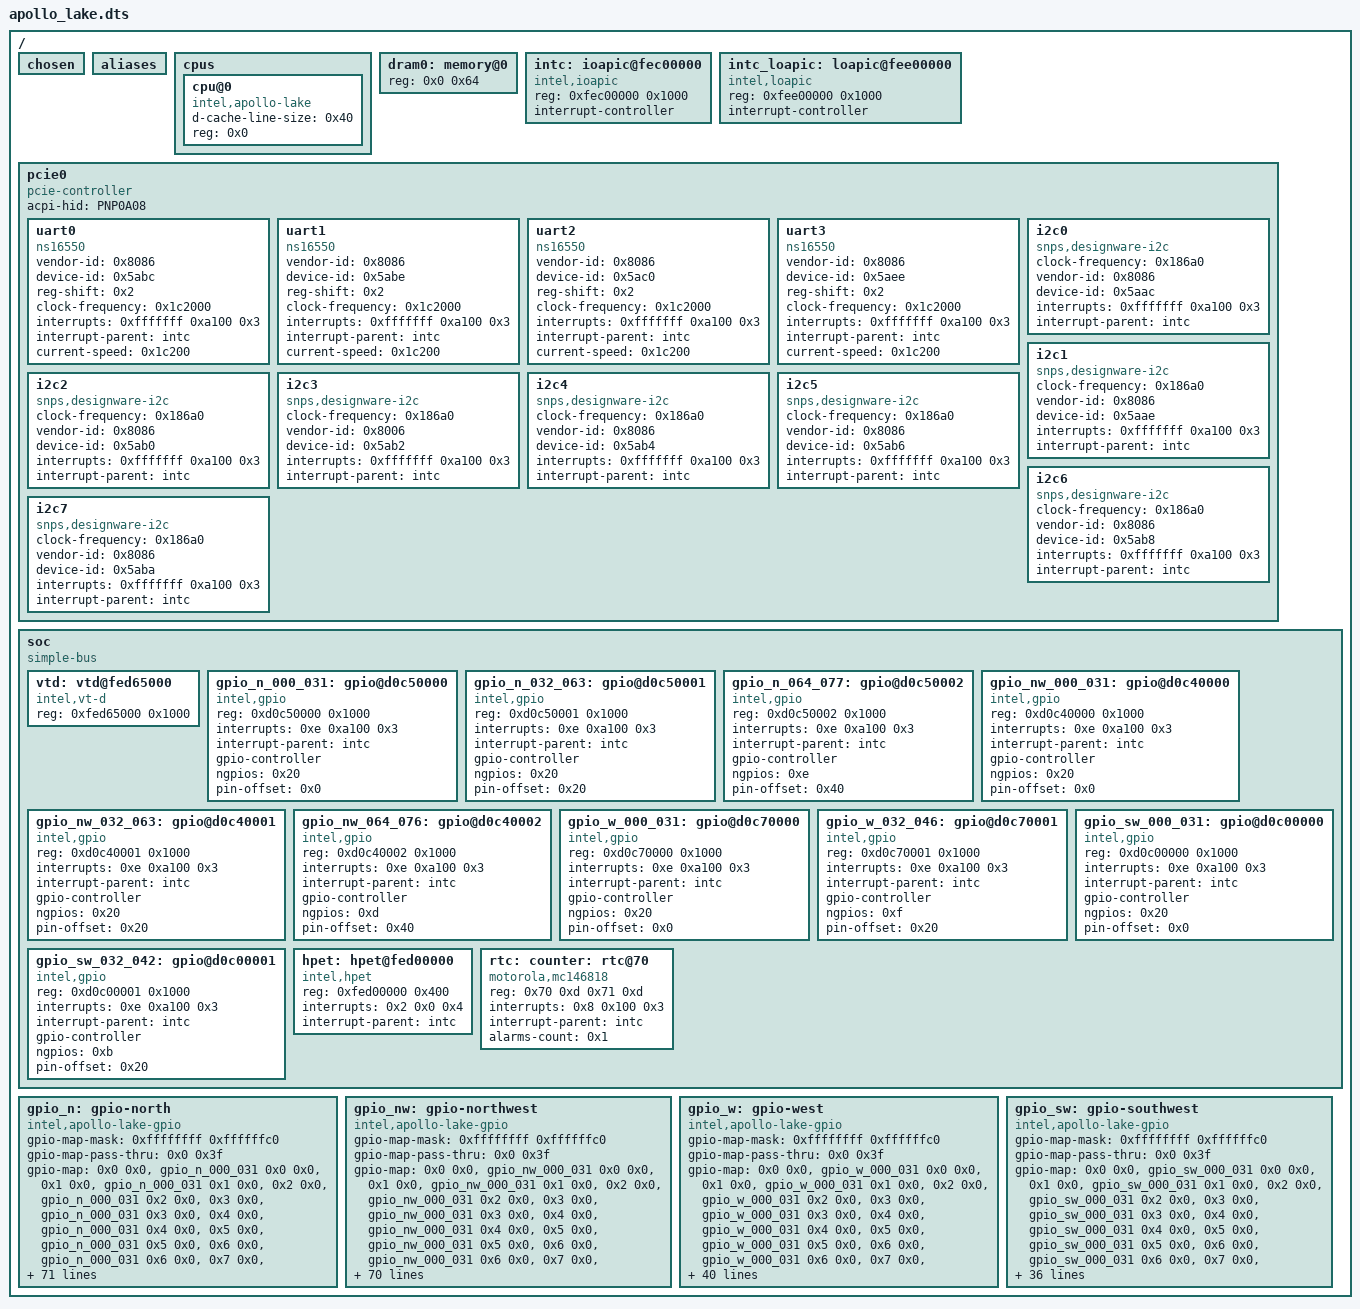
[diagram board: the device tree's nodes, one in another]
/dts-v1/;

/ {
	#address-cells = < 0x1 >;
	#size-cells = < 0x1 >;
	chosen {
	};
	aliases {
	};
	cpus {
		#address-cells = < 0x1 >;
		#size-cells = < 0x0 >;
		cpu@0 {
			device_type = "cpu";
			compatible = "intel,apollo-lake";
			d-cache-line-size = < 0x40 >;
			reg = < 0x0 >;
		};
	};
	dram0: memory@0 {
		device_type = "memory";
		reg = < 0x0 0x64 >;
	};
	intc: ioapic@fec00000 {
		compatible = "intel,ioapic";
		#address-cells = < 0x1 >;
		#interrupt-cells = < 0x3 >;
		reg = < 0xfec00000 0x1000 >;
		interrupt-controller;
		phandle = < 0x1 >;
	};
	intc_loapic: loapic@fee00000 {
		compatible = "intel,loapic";
		reg = < 0xfee00000 0x1000 >;
		interrupt-controller;
		#interrupt-cells = < 0x3 >;
		#address-cells = < 0x1 >;
	};
	pcie0: pcie0 {
		#address-cells = < 0x1 >;
		#size-cells = < 0x1 >;
		compatible = "pcie-controller";
		acpi-hid = "PNP0A08";
		ranges;
		uart0: uart0 {
			compatible = "ns16550";
			vendor-id = < 0x8086 >;
			device-id = < 0x5abc >;
			reg-shift = < 0x2 >;
			clock-frequency = < 0x1c2000 >;
			interrupts = < 0xfffffff 0xa100 0x3 >;
			interrupt-parent = < &intc >;
			status = "okay";
			current-speed = < 0x1c200 >;
		};
		uart1: uart1 {
			compatible = "ns16550";
			vendor-id = < 0x8086 >;
			device-id = < 0x5abe >;
			reg-shift = < 0x2 >;
			clock-frequency = < 0x1c2000 >;
			interrupts = < 0xfffffff 0xa100 0x3 >;
			interrupt-parent = < &intc >;
			status = "okay";
			current-speed = < 0x1c200 >;
		};
		uart2: uart2 {
			compatible = "ns16550";
			vendor-id = < 0x8086 >;
			device-id = < 0x5ac0 >;
			reg-shift = < 0x2 >;
			clock-frequency = < 0x1c2000 >;
			interrupts = < 0xfffffff 0xa100 0x3 >;
			interrupt-parent = < &intc >;
			status = "okay";
			current-speed = < 0x1c200 >;
		};
		uart3: uart3 {
			compatible = "ns16550";
			vendor-id = < 0x8086 >;
			device-id = < 0x5aee >;
			reg-shift = < 0x2 >;
			clock-frequency = < 0x1c2000 >;
			interrupts = < 0xfffffff 0xa100 0x3 >;
			interrupt-parent = < &intc >;
			status = "okay";
			current-speed = < 0x1c200 >;
		};
		i2c0: i2c0 {
			compatible = "snps,designware-i2c";
			clock-frequency = < 0x186a0 >;
			#address-cells = < 0x1 >;
			#size-cells = < 0x0 >;
			vendor-id = < 0x8086 >;
			device-id = < 0x5aac >;
			interrupts = < 0xfffffff 0xa100 0x3 >;
			interrupt-parent = < &intc >;
			status = "okay";
		};
		i2c1: i2c1 {
			compatible = "snps,designware-i2c";
			clock-frequency = < 0x186a0 >;
			#address-cells = < 0x1 >;
			#size-cells = < 0x0 >;
			vendor-id = < 0x8086 >;
			device-id = < 0x5aae >;
			interrupts = < 0xfffffff 0xa100 0x3 >;
			interrupt-parent = < &intc >;
			status = "okay";
		};
		i2c2: i2c2 {
			compatible = "snps,designware-i2c";
			clock-frequency = < 0x186a0 >;
			#address-cells = < 0x1 >;
			#size-cells = < 0x0 >;
			vendor-id = < 0x8086 >;
			device-id = < 0x5ab0 >;
			interrupts = < 0xfffffff 0xa100 0x3 >;
			interrupt-parent = < &intc >;
			status = "okay";
		};
		i2c3: i2c3 {
			compatible = "snps,designware-i2c";
			clock-frequency = < 0x186a0 >;
			#address-cells = < 0x1 >;
			#size-cells = < 0x0 >;
			vendor-id = < 0x8006 >;
			device-id = < 0x5ab2 >;
			interrupts = < 0xfffffff 0xa100 0x3 >;
			interrupt-parent = < &intc >;
			status = "okay";
		};
		i2c4: i2c4 {
			compatible = "snps,designware-i2c";
			clock-frequency = < 0x186a0 >;
			#address-cells = < 0x1 >;
			#size-cells = < 0x0 >;
			vendor-id = < 0x8086 >;
			device-id = < 0x5ab4 >;
			interrupts = < 0xfffffff 0xa100 0x3 >;
			interrupt-parent = < &intc >;
			status = "okay";
		};
		i2c5: i2c5 {
			compatible = "snps,designware-i2c";
			clock-frequency = < 0x186a0 >;
			#address-cells = < 0x1 >;
			#size-cells = < 0x0 >;
			vendor-id = < 0x8086 >;
			device-id = < 0x5ab6 >;
			interrupts = < 0xfffffff 0xa100 0x3 >;
			interrupt-parent = < &intc >;
			status = "okay";
		};
		i2c6: i2c6 {
			compatible = "snps,designware-i2c";
			clock-frequency = < 0x186a0 >;
			#address-cells = < 0x1 >;
			#size-cells = < 0x0 >;
			vendor-id = < 0x8086 >;
			device-id = < 0x5ab8 >;
			interrupts = < 0xfffffff 0xa100 0x3 >;
			interrupt-parent = < &intc >;
			status = "okay";
		};
		i2c7: i2c7 {
			compatible = "snps,designware-i2c";
			clock-frequency = < 0x186a0 >;
			#address-cells = < 0x1 >;
			#size-cells = < 0x0 >;
			vendor-id = < 0x8086 >;
			device-id = < 0x5aba >;
			interrupts = < 0xfffffff 0xa100 0x3 >;
			interrupt-parent = < &intc >;
			status = "okay";
		};
	};
	soc {
		#address-cells = < 0x1 >;
		#size-cells = < 0x1 >;
		compatible = "simple-bus";
		ranges;
		vtd: vtd@fed65000 {
			compatible = "intel,vt-d";
			reg = < 0xfed65000 0x1000 >;
			status = "okay";
		};
		gpio_n_000_031: gpio@d0c50000 {
			compatible = "intel,gpio";
			reg = < 0xd0c50000 0x1000 >;
			interrupts = < 0xe 0xa100 0x3 >;
			interrupt-parent = < &intc >;
			gpio-controller;
			#gpio-cells = < 0x2 >;
			ngpios = < 0x20 >;
			pin-offset = < 0x0 >;
			status = "okay";
			phandle = < 0x2 >;
		};
		gpio_n_032_063: gpio@d0c50001 {
			compatible = "intel,gpio";
			reg = < 0xd0c50001 0x1000 >;
			interrupts = < 0xe 0xa100 0x3 >;
			interrupt-parent = < &intc >;
			gpio-controller;
			#gpio-cells = < 0x2 >;
			ngpios = < 0x20 >;
			pin-offset = < 0x20 >;
			status = "okay";
			phandle = < 0x3 >;
		};
		gpio_n_064_077: gpio@d0c50002 {
			compatible = "intel,gpio";
			reg = < 0xd0c50002 0x1000 >;
			interrupts = < 0xe 0xa100 0x3 >;
			interrupt-parent = < &intc >;
			gpio-controller;
			#gpio-cells = < 0x2 >;
			ngpios = < 0xe >;
			pin-offset = < 0x40 >;
			status = "okay";
			phandle = < 0x4 >;
		};
		gpio_nw_000_031: gpio@d0c40000 {
			compatible = "intel,gpio";
			reg = < 0xd0c40000 0x1000 >;
			interrupts = < 0xe 0xa100 0x3 >;
			interrupt-parent = < &intc >;
			gpio-controller;
			#gpio-cells = < 0x2 >;
			ngpios = < 0x20 >;
			pin-offset = < 0x0 >;
			status = "okay";
			phandle = < 0x5 >;
		};
		gpio_nw_032_063: gpio@d0c40001 {
			compatible = "intel,gpio";
			reg = < 0xd0c40001 0x1000 >;
			interrupts = < 0xe 0xa100 0x3 >;
			interrupt-parent = < &intc >;
			gpio-controller;
			#gpio-cells = < 0x2 >;
			ngpios = < 0x20 >;
			pin-offset = < 0x20 >;
			status = "okay";
			phandle = < 0x6 >;
		};
		gpio_nw_064_076: gpio@d0c40002 {
			compatible = "intel,gpio";
			reg = < 0xd0c40002 0x1000 >;
			interrupts = < 0xe 0xa100 0x3 >;
			interrupt-parent = < &intc >;
			gpio-controller;
			#gpio-cells = < 0x2 >;
			ngpios = < 0xd >;
			pin-offset = < 0x40 >;
			status = "okay";
			phandle = < 0x7 >;
		};
		gpio_w_000_031: gpio@d0c70000 {
			compatible = "intel,gpio";
			reg = < 0xd0c70000 0x1000 >;
			interrupts = < 0xe 0xa100 0x3 >;
			interrupt-parent = < &intc >;
			gpio-controller;
			#gpio-cells = < 0x2 >;
			ngpios = < 0x20 >;
			pin-offset = < 0x0 >;
			status = "okay";
			phandle = < 0x8 >;
		};
		gpio_w_032_046: gpio@d0c70001 {
			compatible = "intel,gpio";
			reg = < 0xd0c70001 0x1000 >;
			interrupts = < 0xe 0xa100 0x3 >;
			interrupt-parent = < &intc >;
			gpio-controller;
			#gpio-cells = < 0x2 >;
			ngpios = < 0xf >;
			pin-offset = < 0x20 >;
			status = "okay";
			phandle = < 0x9 >;
		};
		gpio_sw_000_031: gpio@d0c00000 {
			compatible = "intel,gpio";
			reg = < 0xd0c00000 0x1000 >;
			interrupts = < 0xe 0xa100 0x3 >;
			interrupt-parent = < &intc >;
			gpio-controller;
			#gpio-cells = < 0x2 >;
			ngpios = < 0x20 >;
			pin-offset = < 0x0 >;
			status = "okay";
			phandle = < 0xa >;
		};
		gpio_sw_032_042: gpio@d0c00001 {
			compatible = "intel,gpio";
			reg = < 0xd0c00001 0x1000 >;
			interrupts = < 0xe 0xa100 0x3 >;
			interrupt-parent = < &intc >;
			gpio-controller;
			#gpio-cells = < 0x2 >;
			ngpios = < 0xb >;
			pin-offset = < 0x20 >;
			status = "okay";
			phandle = < 0xb >;
		};
		hpet: hpet@fed00000 {
			compatible = "intel,hpet";
			reg = < 0xfed00000 0x400 >;
			interrupts = < 0x2 0x0 0x4 >;
			interrupt-parent = < &intc >;
			status = "okay";
		};
		rtc: counter: rtc@70 {
			compatible = "motorola,mc146818";
			reg = < 0x70 0xd 0x71 0xd >;
			interrupts = < 0x8 0x100 0x3 >;
			interrupt-parent = < &intc >;
			alarms-count = < 0x1 >;
			status = "okay";
		};
	};
	gpio_n: gpio-north {
		compatible = "intel,apollo-lake-gpio";
		#gpio-cells = < 0x2 >;
		gpio-map-mask = < 0xffffffff 0xffffffc0 >;
		gpio-map-pass-thru = < 0x0 0x3f >;
		gpio-map = < 0x0 0x0 &gpio_n_000_031 0x0 0x0 >, < 0x1 0x0 &gpio_n_000_031 0x1 0x0 >, < 0x2 0x0 &gpio_n_000_031 0x2 0x0 >, < 0x3 0x0 &gpio_n_000_031 0x3 0x0 >, < 0x4 0x0 &gpio_n_000_031 0x4 0x0 >, < 0x5 0x0 &gpio_n_000_031 0x5 0x0 >, < 0x6 0x0 &gpio_n_000_031 0x6 0x0 >, < 0x7 0x0 &gpio_n_000_031 0x7 0x0 >, < 0x8 0x0 &gpio_n_000_031 0x8 0x0 >, < 0x9 0x0 &gpio_n_000_031 0x9 0x0 >, < 0xa 0x0 &gpio_n_000_031 0xa 0x0 >, < 0xb 0x0 &gpio_n_000_031 0xb 0x0 >, < 0xc 0x0 &gpio_n_000_031 0xc 0x0 >, < 0xd 0x0 &gpio_n_000_031 0xd 0x0 >, < 0xe 0x0 &gpio_n_000_031 0xe 0x0 >, < 0xf 0x0 &gpio_n_000_031 0xf 0x0 >, < 0x10 0x0 &gpio_n_000_031 0x10 0x0 >, < 0x11 0x0 &gpio_n_000_031 0x11 0x0 >, < 0x12 0x0 &gpio_n_000_031 0x12 0x0 >, < 0x13 0x0 &gpio_n_000_031 0x13 0x0 >, < 0x14 0x0 &gpio_n_000_031 0x14 0x0 >, < 0x15 0x0 &gpio_n_000_031 0x15 0x0 >, < 0x16 0x0 &gpio_n_000_031 0x16 0x0 >, < 0x17 0x0 &gpio_n_000_031 0x17 0x0 >, < 0x18 0x0 &gpio_n_000_031 0x18 0x0 >, < 0x19 0x0 &gpio_n_000_031 0x19 0x0 >, < 0x1a 0x0 &gpio_n_000_031 0x1a 0x0 >, < 0x1b 0x0 &gpio_n_000_031 0x1b 0x0 >, < 0x1c 0x0 &gpio_n_000_031 0x1c 0x0 >, < 0x1d 0x0 &gpio_n_000_031 0x1d 0x0 >, < 0x1e 0x0 &gpio_n_000_031 0x1e 0x0 >, < 0x1f 0x0 &gpio_n_000_031 0x1f 0x0 >, < 0x20 0x0 &gpio_n_032_063 0x0 0x0 >, < 0x21 0x0 &gpio_n_032_063 0x1 0x0 >, < 0x22 0x0 &gpio_n_032_063 0x2 0x0 >, < 0x23 0x0 &gpio_n_032_063 0x3 0x0 >, < 0x24 0x0 &gpio_n_032_063 0x4 0x0 >, < 0x25 0x0 &gpio_n_032_063 0x5 0x0 >, < 0x26 0x0 &gpio_n_032_063 0x6 0x0 >, < 0x27 0x0 &gpio_n_032_063 0x7 0x0 >, < 0x28 0x0 &gpio_n_032_063 0x8 0x0 >, < 0x29 0x0 &gpio_n_032_063 0x9 0x0 >, < 0x2a 0x0 &gpio_n_032_063 0xa 0x0 >, < 0x2b 0x0 &gpio_n_032_063 0xb 0x0 >, < 0x2c 0x0 &gpio_n_032_063 0xc 0x0 >, < 0x2d 0x0 &gpio_n_032_063 0xd 0x0 >, < 0x2e 0x0 &gpio_n_032_063 0xe 0x0 >, < 0x2f 0x0 &gpio_n_032_063 0xf 0x0 >, < 0x30 0x0 &gpio_n_032_063 0x10 0x0 >, < 0x31 0x0 &gpio_n_032_063 0x11 0x0 >, < 0x32 0x0 &gpio_n_032_063 0x12 0x0 >, < 0x33 0x0 &gpio_n_032_063 0x13 0x0 >, < 0x34 0x0 &gpio_n_032_063 0x14 0x0 >, < 0x35 0x0 &gpio_n_032_063 0x15 0x0 >, < 0x36 0x0 &gpio_n_032_063 0x16 0x0 >, < 0x37 0x0 &gpio_n_032_063 0x17 0x0 >, < 0x38 0x0 &gpio_n_032_063 0x18 0x0 >, < 0x39 0x0 &gpio_n_032_063 0x19 0x0 >, < 0x3a 0x0 &gpio_n_032_063 0x1a 0x0 >, < 0x3b 0x0 &gpio_n_032_063 0x1b 0x0 >, < 0x3c 0x0 &gpio_n_032_063 0x1c 0x0 >, < 0x3d 0x0 &gpio_n_032_063 0x1d 0x0 >, < 0x3e 0x0 &gpio_n_032_063 0x1e 0x0 >, < 0x3f 0x0 &gpio_n_032_063 0x1f 0x0 >, < 0x40 0x0 &gpio_n_064_077 0x0 0x0 >, < 0x41 0x0 &gpio_n_064_077 0x1 0x0 >, < 0x42 0x0 &gpio_n_064_077 0x2 0x0 >, < 0x43 0x0 &gpio_n_064_077 0x3 0x0 >, < 0x44 0x0 &gpio_n_064_077 0x4 0x0 >, < 0x45 0x0 &gpio_n_064_077 0x5 0x0 >, < 0x46 0x0 &gpio_n_064_077 0x6 0x0 >, < 0x47 0x0 &gpio_n_064_077 0x7 0x0 >, < 0x48 0x0 &gpio_n_064_077 0x8 0x0 >, < 0x49 0x0 &gpio_n_064_077 0x9 0x0 >, < 0x4a 0x0 &gpio_n_064_077 0xa 0x0 >, < 0x4b 0x0 &gpio_n_064_077 0xb 0x0 >, < 0x4c 0x0 &gpio_n_064_077 0xc 0x0 >, < 0x4d 0x0 &gpio_n_064_077 0xd 0x0 >;
	};
	gpio_nw: gpio-northwest {
		compatible = "intel,apollo-lake-gpio";
		#gpio-cells = < 0x2 >;
		gpio-map-mask = < 0xffffffff 0xffffffc0 >;
		gpio-map-pass-thru = < 0x0 0x3f >;
		gpio-map = < 0x0 0x0 &gpio_nw_000_031 0x0 0x0 >, < 0x1 0x0 &gpio_nw_000_031 0x1 0x0 >, < 0x2 0x0 &gpio_nw_000_031 0x2 0x0 >, < 0x3 0x0 &gpio_nw_000_031 0x3 0x0 >, < 0x4 0x0 &gpio_nw_000_031 0x4 0x0 >, < 0x5 0x0 &gpio_nw_000_031 0x5 0x0 >, < 0x6 0x0 &gpio_nw_000_031 0x6 0x0 >, < 0x7 0x0 &gpio_nw_000_031 0x7 0x0 >, < 0x8 0x0 &gpio_nw_000_031 0x8 0x0 >, < 0x9 0x0 &gpio_nw_000_031 0x9 0x0 >, < 0xa 0x0 &gpio_nw_000_031 0xa 0x0 >, < 0xb 0x0 &gpio_nw_000_031 0xb 0x0 >, < 0xc 0x0 &gpio_nw_000_031 0xc 0x0 >, < 0xd 0x0 &gpio_nw_000_031 0xd 0x0 >, < 0xe 0x0 &gpio_nw_000_031 0xe 0x0 >, < 0xf 0x0 &gpio_nw_000_031 0xf 0x0 >, < 0x10 0x0 &gpio_nw_000_031 0x10 0x0 >, < 0x11 0x0 &gpio_nw_000_031 0x11 0x0 >, < 0x12 0x0 &gpio_nw_000_031 0x12 0x0 >, < 0x13 0x0 &gpio_nw_000_031 0x13 0x0 >, < 0x14 0x0 &gpio_nw_000_031 0x14 0x0 >, < 0x15 0x0 &gpio_nw_000_031 0x15 0x0 >, < 0x16 0x0 &gpio_nw_000_031 0x16 0x0 >, < 0x17 0x0 &gpio_nw_000_031 0x17 0x0 >, < 0x18 0x0 &gpio_nw_000_031 0x18 0x0 >, < 0x19 0x0 &gpio_nw_000_031 0x19 0x0 >, < 0x1a 0x0 &gpio_nw_000_031 0x1a 0x0 >, < 0x1b 0x0 &gpio_nw_000_031 0x1b 0x0 >, < 0x1c 0x0 &gpio_nw_000_031 0x1c 0x0 >, < 0x1d 0x0 &gpio_nw_000_031 0x1d 0x0 >, < 0x1e 0x0 &gpio_nw_000_031 0x1e 0x0 >, < 0x1f 0x0 &gpio_nw_000_031 0x1f 0x0 >, < 0x20 0x0 &gpio_nw_032_063 0x0 0x0 >, < 0x21 0x0 &gpio_nw_032_063 0x1 0x0 >, < 0x22 0x0 &gpio_nw_032_063 0x2 0x0 >, < 0x23 0x0 &gpio_nw_032_063 0x3 0x0 >, < 0x24 0x0 &gpio_nw_032_063 0x4 0x0 >, < 0x25 0x0 &gpio_nw_032_063 0x5 0x0 >, < 0x26 0x0 &gpio_nw_032_063 0x6 0x0 >, < 0x27 0x0 &gpio_nw_032_063 0x7 0x0 >, < 0x28 0x0 &gpio_nw_032_063 0x8 0x0 >, < 0x29 0x0 &gpio_nw_032_063 0x9 0x0 >, < 0x2a 0x0 &gpio_nw_032_063 0xa 0x0 >, < 0x2b 0x0 &gpio_nw_032_063 0xb 0x0 >, < 0x2c 0x0 &gpio_nw_032_063 0xc 0x0 >, < 0x2d 0x0 &gpio_nw_032_063 0xd 0x0 >, < 0x2e 0x0 &gpio_nw_032_063 0xe 0x0 >, < 0x2f 0x0 &gpio_nw_032_063 0xf 0x0 >, < 0x30 0x0 &gpio_nw_032_063 0x10 0x0 >, < 0x31 0x0 &gpio_nw_032_063 0x11 0x0 >, < 0x32 0x0 &gpio_nw_032_063 0x12 0x0 >, < 0x33 0x0 &gpio_nw_032_063 0x13 0x0 >, < 0x34 0x0 &gpio_nw_032_063 0x14 0x0 >, < 0x35 0x0 &gpio_nw_032_063 0x15 0x0 >, < 0x36 0x0 &gpio_nw_032_063 0x16 0x0 >, < 0x37 0x0 &gpio_nw_032_063 0x17 0x0 >, < 0x38 0x0 &gpio_nw_032_063 0x18 0x0 >, < 0x39 0x0 &gpio_nw_032_063 0x19 0x0 >, < 0x3a 0x0 &gpio_nw_032_063 0x1a 0x0 >, < 0x3b 0x0 &gpio_nw_032_063 0x1b 0x0 >, < 0x3c 0x0 &gpio_nw_032_063 0x1c 0x0 >, < 0x3d 0x0 &gpio_nw_032_063 0x1d 0x0 >, < 0x3e 0x0 &gpio_nw_032_063 0x1e 0x0 >, < 0x3f 0x0 &gpio_nw_032_063 0x1f 0x0 >, < 0x40 0x0 &gpio_nw_064_076 0x0 0x0 >, < 0x41 0x0 &gpio_nw_064_076 0x1 0x0 >, < 0x42 0x0 &gpio_nw_064_076 0x2 0x0 >, < 0x43 0x0 &gpio_nw_064_076 0x3 0x0 >, < 0x44 0x0 &gpio_nw_064_076 0x4 0x0 >, < 0x45 0x0 &gpio_nw_064_076 0x5 0x0 >, < 0x46 0x0 &gpio_nw_064_076 0x6 0x0 >, < 0x47 0x0 &gpio_nw_064_076 0x7 0x0 >, < 0x48 0x0 &gpio_nw_064_076 0x8 0x0 >, < 0x49 0x0 &gpio_nw_064_076 0x9 0x0 >, < 0x4a 0x0 &gpio_nw_064_076 0xa 0x0 >, < 0x4b 0x0 &gpio_nw_064_076 0xb 0x0 >, < 0x4c 0x0 &gpio_nw_064_076 0xc 0x0 >;
	};
	gpio_w: gpio-west {
		compatible = "intel,apollo-lake-gpio";
		#gpio-cells = < 0x2 >;
		gpio-map-mask = < 0xffffffff 0xffffffc0 >;
		gpio-map-pass-thru = < 0x0 0x3f >;
		gpio-map = < 0x0 0x0 &gpio_w_000_031 0x0 0x0 >, < 0x1 0x0 &gpio_w_000_031 0x1 0x0 >, < 0x2 0x0 &gpio_w_000_031 0x2 0x0 >, < 0x3 0x0 &gpio_w_000_031 0x3 0x0 >, < 0x4 0x0 &gpio_w_000_031 0x4 0x0 >, < 0x5 0x0 &gpio_w_000_031 0x5 0x0 >, < 0x6 0x0 &gpio_w_000_031 0x6 0x0 >, < 0x7 0x0 &gpio_w_000_031 0x7 0x0 >, < 0x8 0x0 &gpio_w_000_031 0x8 0x0 >, < 0x9 0x0 &gpio_w_000_031 0x9 0x0 >, < 0xa 0x0 &gpio_w_000_031 0xa 0x0 >, < 0xb 0x0 &gpio_w_000_031 0xb 0x0 >, < 0xc 0x0 &gpio_w_000_031 0xc 0x0 >, < 0xd 0x0 &gpio_w_000_031 0xd 0x0 >, < 0xe 0x0 &gpio_w_000_031 0xe 0x0 >, < 0xf 0x0 &gpio_w_000_031 0xf 0x0 >, < 0x10 0x0 &gpio_w_000_031 0x10 0x0 >, < 0x11 0x0 &gpio_w_000_031 0x11 0x0 >, < 0x12 0x0 &gpio_w_000_031 0x12 0x0 >, < 0x13 0x0 &gpio_w_000_031 0x13 0x0 >, < 0x14 0x0 &gpio_w_000_031 0x14 0x0 >, < 0x15 0x0 &gpio_w_000_031 0x15 0x0 >, < 0x16 0x0 &gpio_w_000_031 0x16 0x0 >, < 0x17 0x0 &gpio_w_000_031 0x17 0x0 >, < 0x18 0x0 &gpio_w_000_031 0x18 0x0 >, < 0x19 0x0 &gpio_w_000_031 0x19 0x0 >, < 0x1a 0x0 &gpio_w_000_031 0x1a 0x0 >, < 0x1b 0x0 &gpio_w_000_031 0x1b 0x0 >, < 0x1c 0x0 &gpio_w_000_031 0x1c 0x0 >, < 0x1d 0x0 &gpio_w_000_031 0x1d 0x0 >, < 0x1e 0x0 &gpio_w_000_031 0x1e 0x0 >, < 0x1f 0x0 &gpio_w_000_031 0x1f 0x0 >, < 0x20 0x0 &gpio_w_032_046 0x0 0x0 >, < 0x21 0x0 &gpio_w_032_046 0x1 0x0 >, < 0x22 0x0 &gpio_w_032_046 0x2 0x0 >, < 0x23 0x0 &gpio_w_032_046 0x3 0x0 >, < 0x24 0x0 &gpio_w_032_046 0x4 0x0 >, < 0x25 0x0 &gpio_w_032_046 0x5 0x0 >, < 0x26 0x0 &gpio_w_032_046 0x6 0x0 >, < 0x27 0x0 &gpio_w_032_046 0x7 0x0 >, < 0x28 0x0 &gpio_w_032_046 0x8 0x0 >, < 0x29 0x0 &gpio_w_032_046 0x9 0x0 >, < 0x2a 0x0 &gpio_w_032_046 0xa 0x0 >, < 0x2b 0x0 &gpio_w_032_046 0xb 0x0 >, < 0x2c 0x0 &gpio_w_032_046 0xc 0x0 >, < 0x2d 0x0 &gpio_w_032_046 0xd 0x0 >, < 0x2e 0x0 &gpio_w_032_046 0xe 0x0 >;
	};
	gpio_sw: gpio-southwest {
		compatible = "intel,apollo-lake-gpio";
		#gpio-cells = < 0x2 >;
		gpio-map-mask = < 0xffffffff 0xffffffc0 >;
		gpio-map-pass-thru = < 0x0 0x3f >;
		gpio-map = < 0x0 0x0 &gpio_sw_000_031 0x0 0x0 >, < 0x1 0x0 &gpio_sw_000_031 0x1 0x0 >, < 0x2 0x0 &gpio_sw_000_031 0x2 0x0 >, < 0x3 0x0 &gpio_sw_000_031 0x3 0x0 >, < 0x4 0x0 &gpio_sw_000_031 0x4 0x0 >, < 0x5 0x0 &gpio_sw_000_031 0x5 0x0 >, < 0x6 0x0 &gpio_sw_000_031 0x6 0x0 >, < 0x7 0x0 &gpio_sw_000_031 0x7 0x0 >, < 0x8 0x0 &gpio_sw_000_031 0x8 0x0 >, < 0x9 0x0 &gpio_sw_000_031 0x9 0x0 >, < 0xa 0x0 &gpio_sw_000_031 0xa 0x0 >, < 0xb 0x0 &gpio_sw_000_031 0xb 0x0 >, < 0xc 0x0 &gpio_sw_000_031 0xc 0x0 >, < 0xd 0x0 &gpio_sw_000_031 0xd 0x0 >, < 0xe 0x0 &gpio_sw_000_031 0xe 0x0 >, < 0xf 0x0 &gpio_sw_000_031 0xf 0x0 >, < 0x10 0x0 &gpio_sw_000_031 0x10 0x0 >, < 0x11 0x0 &gpio_sw_000_031 0x11 0x0 >, < 0x12 0x0 &gpio_sw_000_031 0x12 0x0 >, < 0x13 0x0 &gpio_sw_000_031 0x13 0x0 >, < 0x14 0x0 &gpio_sw_000_031 0x14 0x0 >, < 0x15 0x0 &gpio_sw_000_031 0x15 0x0 >, < 0x16 0x0 &gpio_sw_000_031 0x16 0x0 >, < 0x17 0x0 &gpio_sw_000_031 0x17 0x0 >, < 0x18 0x0 &gpio_sw_000_031 0x18 0x0 >, < 0x19 0x0 &gpio_sw_000_031 0x19 0x0 >, < 0x1a 0x0 &gpio_sw_000_031 0x1a 0x0 >, < 0x1b 0x0 &gpio_sw_000_031 0x1b 0x0 >, < 0x1c 0x0 &gpio_sw_000_031 0x1c 0x0 >, < 0x1d 0x0 &gpio_sw_000_031 0x1d 0x0 >, < 0x1e 0x0 &gpio_sw_000_031 0x1e 0x0 >, < 0x1f 0x0 &gpio_sw_000_031 0x1f 0x0 >, < 0x20 0x0 &gpio_sw_032_042 0x0 0x0 >, < 0x21 0x0 &gpio_sw_032_042 0x1 0x0 >, < 0x22 0x0 &gpio_sw_032_042 0x2 0x0 >, < 0x23 0x0 &gpio_sw_032_042 0x3 0x0 >, < 0x24 0x0 &gpio_sw_032_042 0x4 0x0 >, < 0x25 0x0 &gpio_sw_032_042 0x5 0x0 >, < 0x26 0x0 &gpio_sw_032_042 0x6 0x0 >, < 0x27 0x0 &gpio_sw_032_042 0x7 0x0 >, < 0x28 0x0 &gpio_sw_032_042 0x8 0x0 >, < 0x29 0x0 &gpio_sw_032_042 0x9 0x0 >, < 0x2a 0x0 &gpio_sw_032_042 0xa 0x0 >;
	};
};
